# CY8C5888LTI_LP097 register map
File version: 0.1
CY8C58LP
Registers are 8-bit, read-write, no defined reset value unless marked. A register's access mark holds for its fields unless they carry their own. Offsets are from the block's base; lines under a group give offsets from that group; [hi:lo] are bit positions; {n}, {i} and the like mark numbered series; 'fields as' and 'values as' point back to an identical list; <NAME> marks a mode.

## Memory map
0x00000000 ADC
0x00000000 UART
0x00000000 I2COLED
0x00000000 VG_buffer
0x00000000 AC_source_BuffAmp
0x00000000 AC_source_VDAC8
0x00000000 VG

## UART
Base 0x00000000
0x4000654B TX_UART_TX_DATA — TX Data Register
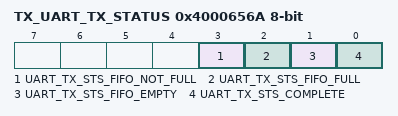
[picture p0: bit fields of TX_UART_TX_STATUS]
0x4000656A TX_UART_TX_STATUS — TX status register
  [3] UART_TX_STS_FIFO_NOT_FULL ro, [2] UART_TX_STS_FIFO_FULL ro, [1] UART_TX_STS_FIFO_EMPTY ro, [0] UART_TX_STS_COMPLETE ro

## VG_buffer
Base 0x00000000
0x400043A4 PM_ACT_CFG4 — Active Power Mode Configuration Register 4
  [3:0] EN_OPAMP — Enables subsystems during active power mode
    0=Blk_0 (Enables analog linear output buffer for Opamp block 0); 2=Blk_1 (Enables analog linear output buffer for Opamp block 1); 4=Blk_2 (Enables analog linear output buffer for Opamp block 2); 8=Blk_3 (Enables analog linear output buffer for Opamp block 3)
0x400043B4 PM_STBY_CFG4 — Standby Power Mode Configuration Register 4
  [3:0] EN_OPAMP — Enables subsystems during standby power mode
    values as PM_ACT_CFG4.EN_OPAMP
0x40004622 OPAMP__TR0 — Analog Output Buffer Trim Register 0
  [4:0] offset_trim — Offset Trim: 420uV typical step size; +/- 6.8mV offset trimmable range
0x40004623 OPAMP__TR1 — Analog Output Buffer Trim Register 1
0x4000585A OPAMP__CR — Analog Output Buffer Configuration Register
  [1:0] pwr_mode — Power Mode
    0=Default_Fast (Default Power mode Fast); 1=Slow (Power Mode Slow); 2=Medium (Power Mode Medium); 3=Fast (Power Mode Fast)
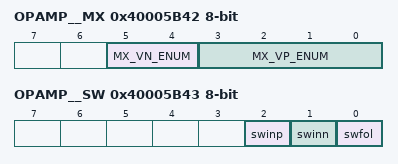
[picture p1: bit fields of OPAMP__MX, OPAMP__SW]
0x40005B42 OPAMP__MX — Analog Buffer Input Selection Register
  [5:4] MX_VN_ENUM — MUX select VN (Negative terminal input)
    0=OPAMP0_MX_VN_DEFAULT (Default - Not Connected (NC)); 1=OPAMP0_MX_VN_AG4 (MUX Selection AGL(4)); 2=OPAMP0_MX_VN_AG6 (MUX Selection AGL(6)); 3=OPAMP0_MX_VN_0x3 (Reserved (NC))
  [3:0] MX_VP_ENUM — MUX select VP (Positive terminal input)
    0=OPAMP0_MX_VP_DEFAULT (Default - Not Connected (NC)); {v}=OPAMP0_MX_VP_AG{v+3} (MUX Selection AGL({v+3})) (v=1..4); {v}=OPAMP0_MX_VP_ABUS{v-5} (MUX Selection ABUSL({v-5})) (v=5..8); 9=OPAMP0_MX_VP_VREF (MUX Selection: OPAMP Voltage Reference); {v}=OPAMP0_MX_VP_H_{0x0+v} (Reserved (NC)) (v=10..15)
0x40005B43 OPAMP__SW — Analog Buffer Routing Switch Register
  [2] swinp — Switch Enable Positive Input
  [1] swinn — Switch Enable Negative Input
  [0] swfol — Switch Enable Follow

## AC_source_BuffAmp
Base 0x00000000
0x400043A4 PM_ACT_CFG4 — Active Power Mode Configuration Register 4
  [3:0] EN_OPAMP — Enables subsystems during active power mode
    0=Blk_0 (Enables analog linear output buffer for Opamp block 0); 2=Blk_1 (Enables analog linear output buffer for Opamp block 1); 4=Blk_2 (Enables analog linear output buffer for Opamp block 2); 8=Blk_3 (Enables analog linear output buffer for Opamp block 3)
0x400043B4 PM_STBY_CFG4 — Standby Power Mode Configuration Register 4
  [3:0] EN_OPAMP — Enables subsystems during standby power mode
    values as PM_ACT_CFG4.EN_OPAMP
0x40004624 OPAMP__TR0 — Analog Output Buffer Trim Register 0
  [4:0] offset_trim — Offset Trim: 420uV typical step size; +/- 6.8mV offset trimmable range
0x40004625 OPAMP__TR1 — Analog Output Buffer Trim Register 1
0x4000585C OPAMP__CR — Analog Output Buffer Configuration Register
  [1:0] pwr_mode — Power Mode
    0=Default_Fast (Default Power mode Fast); 1=Slow (Power Mode Slow); 2=Medium (Power Mode Medium); 3=Fast (Power Mode Fast)
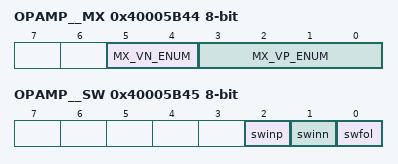
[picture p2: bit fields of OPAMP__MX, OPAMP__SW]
0x40005B44 OPAMP__MX — Analog Buffer Input Selection Register
  [5:4] MX_VN_ENUM — MUX select VN (Negative terminal input)
    0=OPAMP0_MX_VN_DEFAULT (Default - Not Connected (NC)); 1=OPAMP0_MX_VN_AG4 (MUX Selection AGL(4)); 2=OPAMP0_MX_VN_AG6 (MUX Selection AGL(6)); 3=OPAMP0_MX_VN_0x3 (Reserved (NC))
  [3:0] MX_VP_ENUM — MUX select VP (Positive terminal input)
    0=OPAMP0_MX_VP_DEFAULT (Default - Not Connected (NC)); {v}=OPAMP0_MX_VP_AG{v+3} (MUX Selection AGL({v+3})) (v=1..4); {v}=OPAMP0_MX_VP_ABUS{v-5} (MUX Selection ABUSL({v-5})) (v=5..8); 9=OPAMP0_MX_VP_VREF (MUX Selection: OPAMP Voltage Reference); {v}=OPAMP0_MX_VP_H_{0x0+v} (Reserved (NC)) (v=10..15)
0x40005B45 OPAMP__SW — Analog Buffer Routing Switch Register
  [2] swinp — Switch Enable Positive Input
  [1] swinn — Switch Enable Negative Input
  [0] swfol — Switch Enable Follow
